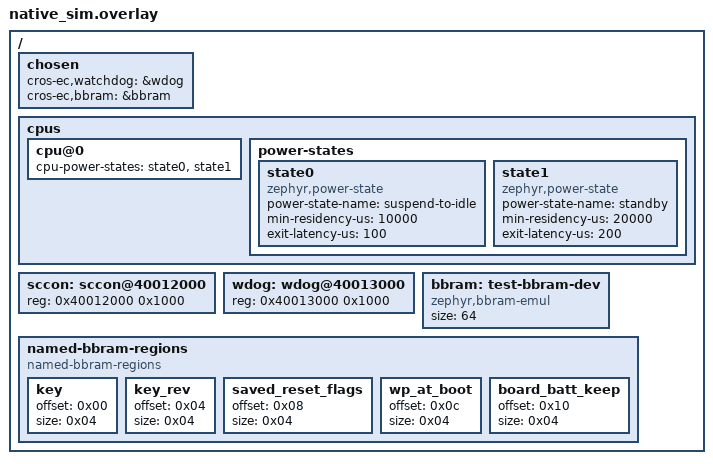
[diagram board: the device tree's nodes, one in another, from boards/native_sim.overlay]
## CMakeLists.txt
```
# Copyright 2026 The ChromiumOS Authors
# Use of this source code is governed by a BSD-style license that can be
# found in the LICENSE file.

cmake_minimum_required(VERSION 3.20.0)
find_package(Zephyr REQUIRED HINTS "${ZEPHYR_BASE}")
project(rts5912_rtmr_test)

add_subdirectory(${PLATFORM_EC}/zephyr/test/test_utils test_utils)

zephyr_include_directories(
	"${ZEPHYR_BASE}/soc/realtek/ec/rts5912"
)

target_compile_options(app PRIVATE
	-include stdio.h
	-DBBRAM_WP_FLAG_INVALID=0xFFFFFFFF
)

target_sources(app PRIVATE
	src/rts5912_rtmr_test.c
	${PLATFORM_EC}/zephyr/drivers/cros_system/cros_system_rtk.c
)
```

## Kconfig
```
# Copyright 2026 The ChromiumOS Authors
# Use of this source code is governed by a BSD-style license that can be
# found in the LICENSE file.

config TEST_PROVIDE_PM_HOOKS
	bool "Provide PM hooks for test purposes"
	default y
	select HAS_PM

source "Kconfig.zephyr"
```

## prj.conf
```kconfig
# Copyright 2026 The ChromiumOS Authors
# Use of this source code is governed by a BSD-style license that can be
# found in the LICENSE file.

CONFIG_ZTEST=y
CONFIG_PLATFORM_EC=y
CONFIG_CROS_EC=y
CONFIG_BBRAM=y
CONFIG_PM=y
CONFIG_CROS_SYSTEM_NONE=y
```

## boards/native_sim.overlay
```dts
/* Copyright 2026 The ChromiumOS Authors
 * Use of this source code is governed by a BSD-style license that can be
 * found in the LICENSE file.
 */

#include <board-overlays/native_sim.dts>

/ {
	chosen {
		cros-ec,watchdog = &wdog;
		cros-ec,bbram = &bbram;
	};

	cpus {
		cpu@0 {
			cpu-power-states = <&state0 &state1>;
		};

		power-states {
			state0: state0 {
				compatible = "zephyr,power-state";
				power-state-name = "suspend-to-idle";
				min-residency-us = <10000>;
				exit-latency-us = <100>;
			};

			state1: state1 {
				compatible = "zephyr,power-state";
				power-state-name = "standby";
				min-residency-us = <20000>;
				exit-latency-us = <200>;
			};
		};
	};

	sccon: sccon@40012000 {
		reg = <0x40012000 0x1000>;
	};

	wdog: wdog@40013000 {
		reg = <0x40013000 0x1000>;
	};

	bbram: test-bbram-dev {
		compatible = "zephyr,bbram-emul";
		size = <64>;
	};

	named-bbram-regions {
		compatible = "named-bbram-regions";

		key {
			offset = <0x00>;
			size = <0x04>;
		};

		key_rev {
			offset = <0x04>;
			size = <0x04>;
		};

		saved_reset_flags {
			offset = <0x08>;
			size = <0x04>;
		};

		wp_at_boot {
			offset = <0x0c>;
			size = <0x04>;
		};

		board_batt_keep {
			offset = <0x10>;
			size = <0x04>;
		};
	};
};
```

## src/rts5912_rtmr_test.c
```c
/* Copyright 2026 The ChromiumOS Authors
 * Use of this source code is governed by a BSD-style license that can be
 * found in the LICENSE file.
 */

#include "drivers/cros_system.h"
#include "system.h"

#include <zephyr/device.h>
#include <zephyr/drivers/watchdog.h>
#include <zephyr/fff.h>
#include <zephyr/kernel.h>
#include <zephyr/pm/pm.h>
#include <zephyr/pm/state.h>
#include <zephyr/ztest.h>

#include <soc_clock.h>
#include <sys/mman.h>

FAKE_VOID_FUNC(watchdog_reload);
FAKE_VALUE_FUNC(uint64_t, rts5912_clock_get_sleep_ticks);

static const struct wdt_driver_api wdog_dummy_api;

DEVICE_DT_DEFINE(DT_NODELABEL(wdog), NULL, NULL, NULL, NULL, PRE_KERNEL_1, 1,
		 &wdog_dummy_api);

/* Map RTS5912 MMIO register windows before PRE_KERNEL_1 SYS_INIT runs. */
static int map_rtk_mmio_regs(void)
{
	void *p1 = mmap((void *)0x40010000, 0x4000, PROT_READ | PROT_WRITE,
			MAP_PRIVATE | MAP_ANONYMOUS | MAP_FIXED, -1, 0);
	void *p2 = mmap((void *)0x40104000, 0x1000, PROT_READ | PROT_WRITE,
			MAP_PRIVATE | MAP_ANONYMOUS | MAP_FIXED, -1, 0);

	__ASSERT_NO_MSG(p1 != MAP_FAILED);
	__ASSERT_NO_MSG(p2 != MAP_FAILED);

	/* Mark OTP controller ready (OTP_STS_PDSTB_MSK = 0x04). */
	*(volatile uint32_t *)0x40010ea0 = 0x04;
	return 0;
}
SYS_INIT(map_rtk_mmio_regs, EARLY, 0);

void pm_state_set(enum pm_state state, uint8_t substate_id)
{
	ARG_UNUSED(state);
	ARG_UNUSED(substate_id);

	k_cpu_idle();
}

void pm_state_exit_post_ops(enum pm_state state, uint8_t substate_id)
{
	ARG_UNUSED(state);
	ARG_UNUSED(substate_id);

	irq_unlock(0);
}

static void rts5912_rtmr_before(void *fixture)
{
	ARG_UNUSED(fixture);

	RESET_FAKE(watchdog_reload);
	RESET_FAKE(rts5912_clock_get_sleep_ticks);
}

ZTEST(rts5912_rtmr, test_watchdog_reload_on_suspend_to_idle)
{
	const struct pm_state_info s2idle = {
		.state = PM_STATE_SUSPEND_TO_IDLE,
	};
	const struct pm_state_info standby = {
		.state = PM_STATE_STANDBY,
	};

	zassert_true(pm_state_force(0U, &s2idle));
	k_sleep(K_MSEC(1));
	zassert_equal(watchdog_reload_fake.call_count, 1,
		      "Expected watchdog_reload on PM_STATE_SUSPEND_TO_IDLE");

	RESET_FAKE(watchdog_reload);
	zassert_true(pm_state_force(0U, &standby));
	k_sleep(K_MSEC(1));
	zassert_equal(watchdog_reload_fake.call_count, 0,
		      "Unexpected watchdog_reload on PM_STATE_STANDBY");
}

ZTEST_SUITE(rts5912_rtmr, NULL, NULL, rts5912_rtmr_before, NULL, NULL);
```
